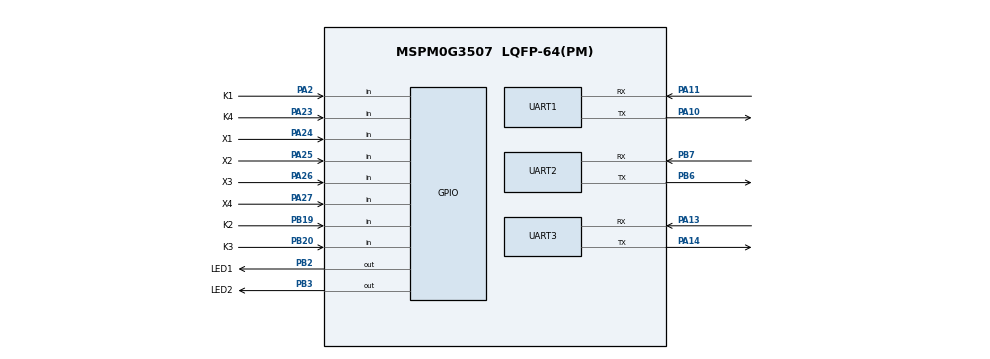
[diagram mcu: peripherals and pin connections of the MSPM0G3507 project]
/**
 * These arguments were used when this file was generated. They will be automatically applied on subsequent loads
 * via the GUI or CLI. Run CLI with '--help' for additional information on how to override these arguments.
 * @cliArgs --device "MSPM0G350X" --part "Default" --package "LQFP-64(PM)" --product "mspm0_sdk@2.02.00.05"
 * @v2CliArgs --device "MSPM0G3507" --package "LQFP-64(PM)" --product "mspm0_sdk@2.02.00.05"
 * @versions {"tool":"1.21.1+3772"}
 */

/**
 * Import the modules used in this configuration.
 */
const GPIO    = scripting.addModule("/ti/driverlib/GPIO", {}, false);
const GPIO1   = GPIO.addInstance();
const GPIO2   = GPIO.addInstance();
const GPIO3   = GPIO.addInstance();
const GPIO4   = GPIO.addInstance();
const SYSCTL  = scripting.addModule("/ti/driverlib/SYSCTL");
const SYSTICK = scripting.addModule("/ti/driverlib/SYSTICK");
const UART    = scripting.addModule("/ti/driverlib/UART", {}, false);
const UART1   = UART.addInstance();
const UART2   = UART.addInstance();
const UART3   = UART.addInstance();

/**
 * Write custom configuration values to the imported modules.
 */
const gate7  = system.clockTree["MFCLKGATE"];
gate7.enable = true;

GPIO1.$name                          = "Sensor";
GPIO1.associatedPins.create(4);
GPIO1.associatedPins[0].$name        = "X1";
GPIO1.associatedPins[0].direction    = "INPUT";
GPIO1.associatedPins[0].assignedPort = "PORTA";
GPIO1.associatedPins[0].pin.$assign  = "PA24";
GPIO1.associatedPins[1].$name        = "X2";
GPIO1.associatedPins[1].direction    = "INPUT";
GPIO1.associatedPins[1].assignedPort = "PORTA";
GPIO1.associatedPins[1].pin.$assign  = "PA25";
GPIO1.associatedPins[2].$name        = "X3";
GPIO1.associatedPins[2].direction    = "INPUT";
GPIO1.associatedPins[2].assignedPort = "PORTA";
GPIO1.associatedPins[2].pin.$assign  = "PA26";
GPIO1.associatedPins[3].$name        = "X4";
GPIO1.associatedPins[3].direction    = "INPUT";
GPIO1.associatedPins[3].assignedPort = "PORTA";
GPIO1.associatedPins[3].pin.$assign  = "PA27";

GPIO2.$name                          = "LED";
GPIO2.associatedPins.create(2);
GPIO2.associatedPins[0].$name        = "LED1";
GPIO2.associatedPins[0].direction    = "OUTPUT";
GPIO2.associatedPins[0].assignedPort = "PORTB";
GPIO2.associatedPins[0].pin.$assign  = "PB2";
GPIO2.associatedPins[1].$name        = "LED2";
GPIO2.associatedPins[1].direction    = "OUTPUT";
GPIO2.associatedPins[1].assignedPort = "PORTB";
GPIO2.associatedPins[1].pin.$assign  = "PB3";

GPIO3.$name                          = "KEY_A";
GPIO3.associatedPins.create(2);
GPIO3.associatedPins[0].$name        = "K1";
GPIO3.associatedPins[0].direction    = "INPUT";
GPIO3.associatedPins[0].assignedPort = "PORTA";
GPIO3.associatedPins[0].pin.$assign  = "PA2";
GPIO3.associatedPins[1].$name        = "K4";
GPIO3.associatedPins[1].direction    = "INPUT";
GPIO3.associatedPins[1].assignedPort = "PORTA";
GPIO3.associatedPins[1].pin.$assign  = "PA23";

GPIO4.$name                          = "KEY_B";
GPIO4.associatedPins.create(2);
GPIO4.associatedPins[0].$name        = "K2";
GPIO4.associatedPins[0].direction    = "INPUT";
GPIO4.associatedPins[0].assignedPort = "PORTB";
GPIO4.associatedPins[0].pin.$assign  = "PB19";
GPIO4.associatedPins[1].$name        = "K3";
GPIO4.associatedPins[1].direction    = "INPUT";
GPIO4.associatedPins[1].assignedPort = "PORTB";
GPIO4.associatedPins[1].pin.$assign  = "PB20";

const Board = scripting.addModule("/ti/driverlib/Board", {}, false);

SYSCTL.forceDefaultClkConfig = true;
SYSCTL.clockTreeEn           = true;

SYSTICK.periodEnable  = true;
SYSTICK.systickEnable = true;
SYSTICK.period        = 32;

UART1.$name                    = "UART_0";
UART1.uartClkSrc               = "MFCLK";
UART1.enabledInterrupts        = ["RX"];
UART1.targetBaudRate           = 115200;
UART1.peripheral.rxPin.$assign = "PA11";
UART1.peripheral.txPin.$assign = "PA10";
UART1.txPinConfig.$name        = "ti_driverlib_gpio_GPIOPinGeneric0";
UART1.rxPinConfig.$name        = "ti_driverlib_gpio_GPIOPinGeneric1";

UART2.$name                    = "UART_1";
UART2.targetBaudRate           = 115200;
UART2.uartClkSrc               = "MFCLK";
UART2.enabledInterrupts        = ["RX"];
UART2.peripheral.$assign       = "UART1";
UART2.peripheral.rxPin.$assign = "PB7";
UART2.peripheral.txPin.$assign = "PB6";
UART2.txPinConfig.$name        = "ti_driverlib_gpio_GPIOPinGeneric2";
UART2.rxPinConfig.$name        = "ti_driverlib_gpio_GPIOPinGeneric3";

UART3.$name                            = "UART_3";
UART3.uartClkSrc                       = "MFCLK";
UART3.enabledInterrupts                = ["RX"];
UART3.targetBaudRate                   = 115200;
UART3.peripheral.$assign               = "UART3";
UART3.peripheral.rxPin.$assign         = "PA13";
UART3.peripheral.txPin.$assign         = "PA14";
UART3.txPinConfig.$name                = "ti_driverlib_gpio_GPIOPinGeneric4";
UART3.txPinConfig.direction            = scripting.forceWrite("OUTPUT");
UART3.txPinConfig.hideOutputInversion  = scripting.forceWrite(false);
UART3.txPinConfig.onlyInternalResistor = scripting.forceWrite(false);
UART3.txPinConfig.passedPeripheralType = scripting.forceWrite("Digital");
UART3.rxPinConfig.$name                = "ti_driverlib_gpio_GPIOPinGeneric5";
UART3.rxPinConfig.hideOutputInversion  = scripting.forceWrite(false);
UART3.rxPinConfig.onlyInternalResistor = scripting.forceWrite(false);
UART3.rxPinConfig.passedPeripheralType = scripting.forceWrite("Digital");

/**
 * Pinmux solution for unlocked pins/peripherals. This ensures that minor changes to the automatic solver in a future
 * version of the tool will not impact the pinmux you originally saw.  These lines can be completely deleted in order to
 * re-solve from scratch.
 */
Board.peripheral.$suggestSolution          = "DEBUGSS";
Board.peripheral.swclkPin.$suggestSolution = "PA20";
Board.peripheral.swdioPin.$suggestSolution = "PA19";
UART1.peripheral.$suggestSolution          = "UART0";
